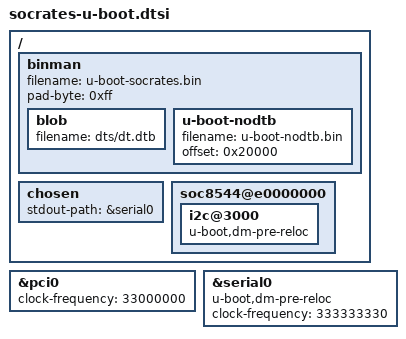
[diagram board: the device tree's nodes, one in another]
// SPDX-License-Identifier: GPL-2.0+
/*
 * Copyright (C) 2019
 * Heiko Schocher, DENX Software Engineering, hs@denx.de
 */
/ {
	binman {
		filename = "u-boot-socrates.bin";
		pad-byte = <0xff>;
		// Place dtb one sector before u-boot-nodtb.bin
		blob {
			filename = "dts/dt.dtb";
		};
		u-boot-nodtb {
			filename = "u-boot-nodtb.bin";
			offset = <0x20000>;
		};
	};

	chosen {
		stdout-path = &serial0;
	};

	soc8544@e0000000 {
		i2c@3000 {
			u-boot,dm-pre-reloc;
		};
	};
};

&pci0 {
	clock-frequency = <33000000>;
	ranges = <0x02000000 0x0 0x80000000 0x80000000 0x0 0x20000000
		  0x01000000 0x0 0xe2000000 0xe2000000 0x0 0x01000000>;
};

&serial0 {
	u-boot,dm-pre-reloc;
	clock-frequency = <333333330>;
};
